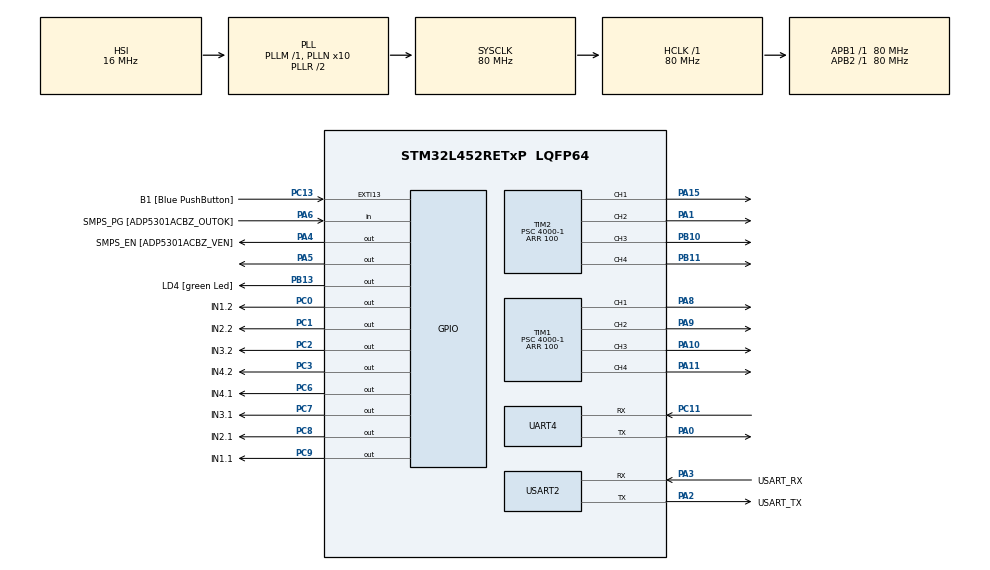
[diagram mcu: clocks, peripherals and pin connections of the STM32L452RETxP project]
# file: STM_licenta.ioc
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Mcu.Family=STM32L4
Mcu.Name=STM32L452RETxP
Mcu.Package=LQFP64
NVIC.PriorityGroup=NVIC_PRIORITYGROUP_4
NVIC.UART4_IRQn=true\:0\:0\:false\:false\:true\:true\:true\:true
PA0.Mode=Asynchronous
PA0.Signal=UART4_TX
PA1.Signal=S_TIM2_CH2
PA10.Signal=S_TIM1_CH3
PA11.Signal=S_TIM1_CH4
PA13\ (JTMS/SWDIO).GPIO_Label=TMS
PA13\ (JTMS/SWDIO).Mode=Serial_Wire
PA13\ (JTMS/SWDIO).Signal=SYS_JTMS-SWDIO
PA14\ (JTCK/SWCLK).GPIO_Label=TCK
PA14\ (JTCK/SWCLK).Mode=Serial_Wire
PA14\ (JTCK/SWCLK).Signal=SYS_JTCK-SWCLK
PA15\ (JTDI).Signal=S_TIM2_CH1
PA2.GPIO_Label=USART_TX
PA2.GPIO_Mode=GPIO_MODE_AF_PP
PA2.GPIO_PuPd=GPIO_NOPULL
PA2.GPIO_Speed=GPIO_SPEED_FREQ_VERY_HIGH
PA2.Mode=Asynchronous
PA2.Signal=USART2_TX
PA3.GPIO_Label=USART_RX
PA3.GPIO_Mode=GPIO_MODE_AF_PP
PA3.GPIO_PuPd=GPIO_NOPULL
PA3.GPIO_Speed=GPIO_SPEED_FREQ_VERY_HIGH
PA3.Mode=Asynchronous
PA3.Signal=USART2_RX
PA4.GPIO_Label=SMPS_EN [ADP5301ACBZ_VEN]
PA4.Signal=GPIO_Output
PA5.Signal=GPIO_Output
PA6.GPIO_Label=SMPS_PG [ADP5301ACBZ_OUTOK]
PA6.GPIO_PuPd=GPIO_PULLUP
PA6.Signal=GPIO_Input
PA8.Signal=S_TIM1_CH1
PA9.Signal=S_TIM1_CH2
PB10.Signal=S_TIM2_CH3
PB11.Signal=S_TIM2_CH4
PB13.GPIO_Label=LD4 [green Led]
PB13.Signal=GPIO_Output
PB3\ (JTDO/TRACESWO).GPIO_Label=SWO
PB3\ (JTDO/TRACESWO).Signal=SYS_JTDO-SWO
PC0.GPIO_Label=IN1.2
PC0.Signal=GPIO_Output
PC1.GPIO_Label=IN2.2
PC1.Signal=GPIO_Output
PC11.Mode=Asynchronous
PC11.Signal=UART4_RX
PC13.GPIO_Label=B1 [Blue PushButton]
PC13.GPIO_ModeDefaultEXTI=GPIO_MODE_IT_FALLING
PC13.GPIO_PuPd=GPIO_NOPULL
PC13.Signal=GPXTI13
PC14-OSC32_IN\ (PC14).Mode=LSE-External-Oscillator
PC14-OSC32_IN\ (PC14).Signal=RCC_OSC32_IN
PC15-OSC32_OUT\ (PC15).Mode=LSE-External-Oscillator
PC15-OSC32_OUT\ (PC15).Signal=RCC_OSC32_OUT
PC2.GPIO_Label=IN3.2
PC2.Signal=GPIO_Output
PC3.GPIO_Label=IN4.2
PC3.Signal=GPIO_Output
PC6.GPIO_Label=IN4.1
PC6.Signal=GPIO_Output
PC7.GPIO_Label=IN3.1
PC7.Signal=GPIO_Output
PC8.GPIO_Label=IN2.1
PC8.Signal=GPIO_Output
PC9.GPIO_Label=IN1.1
PC9.Signal=GPIO_Output
PH0-OSC_IN\ (PH0).GPIO_Label=MCO
PH0-OSC_IN\ (PH0).Mode=HSE-External-Clock-Source
PH0-OSC_IN\ (PH0).Signal=RCC_OSC_IN
PH1-OSC_OUT\ (PH1).Signal=RCC_OSC_OUT
ProjectManager.HeapSize=0x200
ProjectManager.StackSize=0x400
ProjectManager.TargetToolchain=STM32CubeIDE
RCC.ADCFreq_Value=64000000
RCC.AHBFreq_Value=80000000
RCC.APB1Freq_Value=80000000
RCC.APB1TimFreq_Value=80000000
RCC.APB2Freq_Value=80000000
RCC.APB2TimFreq_Value=80000000
RCC.CortexFreq_Value=80000000
RCC.HCLKFreq_Value=80000000
RCC.HSE_VALUE=8000000
RCC.HSI48_VALUE=48000000
RCC.HSI_VALUE=16000000
RCC.MSI_VALUE=4000000
RCC.PLLN=10
RCC.PLLSourceVirtual=RCC_PLLSOURCE_HSI
RCC.PREFETCH_ENABLE=1
RCC.SYSCLKFreq_VALUE=80000000
RCC.SYSCLKSource=RCC_SYSCLKSOURCE_PLLCLK
RCC.USBFreq_Value=64000000
RCC.VCOOutputFreq_Value=160000000
SH.S_TIM1_CH1.0=TIM1_CH1,PWM Generation1 CH1
SH.S_TIM1_CH2.0=TIM1_CH2,PWM Generation2 CH2
SH.S_TIM1_CH3.0=TIM1_CH3,PWM Generation3 CH3
SH.S_TIM1_CH4.0=TIM1_CH4,PWM Generation4 CH4
SH.S_TIM2_CH1.0=TIM2_CH1,PWM Generation1 CH1
SH.S_TIM2_CH2.0=TIM2_CH2,PWM Generation2 CH2
SH.S_TIM2_CH3.0=TIM2_CH3,PWM Generation3 CH3
SH.S_TIM2_CH4.0=TIM2_CH4,PWM Generation4 CH4
TIM1.Channel-PWM\ Generation1\ CH1=TIM_CHANNEL_1
TIM1.Channel-PWM\ Generation2\ CH2=TIM_CHANNEL_2
TIM1.Channel-PWM\ Generation3\ CH3=TIM_CHANNEL_3
TIM1.Channel-PWM\ Generation4\ CH4=TIM_CHANNEL_4
TIM1.Period=100
TIM1.Prescaler=4000-1
TIM2.Channel-PWM\ Generation1\ CH1=TIM_CHANNEL_1
TIM2.Channel-PWM\ Generation2\ CH2=TIM_CHANNEL_2
TIM2.Channel-PWM\ Generation3\ CH3=TIM_CHANNEL_3
TIM2.Channel-PWM\ Generation4\ CH4=TIM_CHANNEL_4
TIM2.Period=100
TIM2.Prescaler=4000-1
USART2.VirtualMode-Asynchronous=VM_ASYNC
VP_TIM1_VS_ClockSourceINT.Mode=Internal
VP_TIM2_VS_ClockSourceINT.Mode=Internal
board=NUCLEO-L452RE-P

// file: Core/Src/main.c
/* USER CODE BEGIN Header */
/**
  ******************************************************************************
  * @file           : main.c
  * @brief          : Main program body
  ******************************************************************************
  * @attention
  *
  * Copyright (c) 2025 STMicroelectronics.
  * All rights reserved.
  *
  * This software is licensed under terms that can be found in the LICENSE file
  * in the root directory of this software component.
  * If no LICENSE file comes with this software, it is provided AS-IS.
  *
  ******************************************************************************
  */
/* USER CODE END Header */
#include "main.h"

/* USER CODE BEGIN Includes */

#include <string.h>

/* USER CODE END Includes */

TIM_HandleTypeDef htim1;
TIM_HandleTypeDef htim2;

UART_HandleTypeDef huart4;
UART_HandleTypeDef huart2;

void SystemClock_Config(void);
static void MX_GPIO_Init(void);
static void MX_USART2_UART_Init(void);
static void MX_UART4_Init(void);
static void MX_TIM1_Init(void);
static void MX_TIM2_Init(void);

/* USER CODE BEGIN 0 */

uint8_t rx_byte;
char rx_buffer[32];
uint8_t rx_index = 0;

/* USER CODE END 0 */

int main(void)
{

  /* MCU Configuration--------------------------------------------------------*/

  /* Reset of all peripherals, Initializes the Flash interface and the Systick. */
  HAL_Init();

  /* Configure the system clock */
  SystemClock_Config();

  /* Initialize all configured peripherals */
  MX_GPIO_Init();
  MX_USART2_UART_Init();
  MX_UART4_Init();
  MX_TIM1_Init();
  MX_TIM2_Init();
  /* USER CODE BEGIN 2 */

  HAL_UART_Receive_IT(&huart4, &rx_byte, 1);
  HAL_TIM_PWM_Start(&htim1, TIM_CHANNEL_1);
  HAL_TIM_PWM_Start(&htim1, TIM_CHANNEL_2);
  HAL_TIM_PWM_Start(&htim1, TIM_CHANNEL_3);
  HAL_TIM_PWM_Start(&htim1, TIM_CHANNEL_4);
  HAL_TIM_PWM_Start(&htim2, TIM_CHANNEL_1);
  HAL_TIM_PWM_Start(&htim2, TIM_CHANNEL_2);
  HAL_TIM_PWM_Start(&htim2, TIM_CHANNEL_3);
  HAL_TIM_PWM_Start(&htim2, TIM_CHANNEL_4);

  /* USER CODE END 2 */

  /* Infinite loop */
  while (1)
  {

  }
}

void SystemClock_Config(void)
{
  RCC_OscInitTypeDef RCC_OscInitStruct = {0};
  RCC_ClkInitTypeDef RCC_ClkInitStruct = {0};

  /** Configure the main internal regulator output voltage
  */
  if (HAL_PWREx_ControlVoltageScaling(PWR_REGULATOR_VOLTAGE_SCALE1) != HAL_OK)
  {
    Error_Handler();
  }

  /** Initializes the RCC Oscillators according to the specified parameters
  * in the RCC_OscInitTypeDef structure.
  */
  RCC_OscInitStruct.OscillatorType = RCC_OSCILLATORTYPE_HSI;
  RCC_OscInitStruct.HSIState = RCC_HSI_ON;
  RCC_OscInitStruct.HSICalibrationValue = 64;
  RCC_OscInitStruct.PLL.PLLState = RCC_PLL_ON;
  RCC_OscInitStruct.PLL.PLLSource = RCC_PLLSOURCE_HSI;
  RCC_OscInitStruct.PLL.PLLM = 1;
  RCC_OscInitStruct.PLL.PLLN = 10;
  RCC_OscInitStruct.PLL.PLLP = RCC_PLLP_DIV7;
  RCC_OscInitStruct.PLL.PLLQ = RCC_PLLQ_DIV2;
  RCC_OscInitStruct.PLL.PLLR = RCC_PLLR_DIV2;
  if (HAL_RCC_OscConfig(&RCC_OscInitStruct) != HAL_OK)
  {
    Error_Handler();
  }

  /** Initializes the CPU, AHB and APB buses clocks
  */
  RCC_ClkInitStruct.ClockType = RCC_CLOCKTYPE_HCLK|RCC_CLOCKTYPE_SYSCLK
                              |RCC_CLOCKTYPE_PCLK1|RCC_CLOCKTYPE_PCLK2;
  RCC_ClkInitStruct.SYSCLKSource = RCC_SYSCLKSOURCE_PLLCLK;
  RCC_ClkInitStruct.AHBCLKDivider = RCC_SYSCLK_DIV1;
  RCC_ClkInitStruct.APB1CLKDivider = RCC_HCLK_DIV1;
  RCC_ClkInitStruct.APB2CLKDivider = RCC_HCLK_DIV1;

  if (HAL_RCC_ClockConfig(&RCC_ClkInitStruct, FLASH_LATENCY_4) != HAL_OK)
  {
    Error_Handler();
  }
}

static void MX_TIM1_Init(void)
{

  TIM_ClockConfigTypeDef sClockSourceConfig = {0};
  TIM_MasterConfigTypeDef sMasterConfig = {0};
  TIM_OC_InitTypeDef sConfigOC = {0};
  TIM_BreakDeadTimeConfigTypeDef sBreakDeadTimeConfig = {0};

  htim1.Instance = TIM1;
  htim1.Init.Prescaler = 4000-1;
  htim1.Init.CounterMode = TIM_COUNTERMODE_UP;
  htim1.Init.Period = 100;
  htim1.Init.ClockDivision = TIM_CLOCKDIVISION_DIV1;
  htim1.Init.RepetitionCounter = 0;
  htim1.Init.AutoReloadPreload = TIM_AUTORELOAD_PRELOAD_DISABLE;
  if (HAL_TIM_Base_Init(&htim1) != HAL_OK)
  {
    Error_Handler();
  }
  sClockSourceConfig.ClockSource = TIM_CLOCKSOURCE_INTERNAL;
  if (HAL_TIM_ConfigClockSource(&htim1, &sClockSourceConfig) != HAL_OK)
  {
    Error_Handler();
  }
  if (HAL_TIM_PWM_Init(&htim1) != HAL_OK)
  {
    Error_Handler();
  }
  sMasterConfig.MasterOutputTrigger = TIM_TRGO_RESET;
  sMasterConfig.MasterOutputTrigger2 = TIM_TRGO2_RESET;
  sMasterConfig.MasterSlaveMode = TIM_MASTERSLAVEMODE_DISABLE;
  if (HAL_TIMEx_MasterConfigSynchronization(&htim1, &sMasterConfig) != HAL_OK)
  {
    Error_Handler();
  }
  sConfigOC.OCMode = TIM_OCMODE_PWM1;
  sConfigOC.Pulse = 0;
  sConfigOC.OCPolarity = TIM_OCPOLARITY_HIGH;
  sConfigOC.OCNPolarity = TIM_OCNPOLARITY_HIGH;
  sConfigOC.OCFastMode = TIM_OCFAST_DISABLE;
  sConfigOC.OCIdleState = TIM_OCIDLESTATE_RESET;
  sConfigOC.OCNIdleState = TIM_OCNIDLESTATE_RESET;
  if (HAL_TIM_PWM_ConfigChannel(&htim1, &sConfigOC, TIM_CHANNEL_1) != HAL_OK)
  {
    Error_Handler();
  }
  if (HAL_TIM_PWM_ConfigChannel(&htim1, &sConfigOC, TIM_CHANNEL_2) != HAL_OK)
  {
    Error_Handler();
  }
  if (HAL_TIM_PWM_ConfigChannel(&htim1, &sConfigOC, TIM_CHANNEL_3) != HAL_OK)
  {
    Error_Handler();
  }
  if (HAL_TIM_PWM_ConfigChannel(&htim1, &sConfigOC, TIM_CHANNEL_4) != HAL_OK)
  {
    Error_Handler();
  }
  sBreakDeadTimeConfig.OffStateRunMode = TIM_OSSR_DISABLE;
  sBreakDeadTimeConfig.OffStateIDLEMode = TIM_OSSI_DISABLE;
  sBreakDeadTimeConfig.LockLevel = TIM_LOCKLEVEL_OFF;
  sBreakDeadTimeConfig.DeadTime = 0;
  sBreakDeadTimeConfig.BreakState = TIM_BREAK_DISABLE;
  sBreakDeadTimeConfig.BreakPolarity = TIM_BREAKPOLARITY_HIGH;
  sBreakDeadTimeConfig.BreakFilter = 0;
  sBreakDeadTimeConfig.Break2State = TIM_BREAK2_DISABLE;
  sBreakDeadTimeConfig.Break2Polarity = TIM_BREAK2POLARITY_HIGH;
  sBreakDeadTimeConfig.Break2Filter = 0;
  sBreakDeadTimeConfig.AutomaticOutput = TIM_AUTOMATICOUTPUT_DISABLE;
  if (HAL_TIMEx_ConfigBreakDeadTime(&htim1, &sBreakDeadTimeConfig) != HAL_OK)
  {
    Error_Handler();
  }
  HAL_TIM_MspPostInit(&htim1);

}

static void MX_TIM2_Init(void)
{

  TIM_ClockConfigTypeDef sClockSourceConfig = {0};
  TIM_MasterConfigTypeDef sMasterConfig = {0};
  TIM_OC_InitTypeDef sConfigOC = {0};

  htim2.Instance = TIM2;
  htim2.Init.Prescaler = 4000-1;
  htim2.Init.CounterMode = TIM_COUNTERMODE_UP;
  htim2.Init.Period = 100;
  htim2.Init.ClockDivision = TIM_CLOCKDIVISION_DIV1;
  htim2.Init.AutoReloadPreload = TIM_AUTORELOAD_PRELOAD_DISABLE;
  if (HAL_TIM_Base_Init(&htim2) != HAL_OK)
  {
    Error_Handler();
  }
  sClockSourceConfig.ClockSource = TIM_CLOCKSOURCE_INTERNAL;
  if (HAL_TIM_ConfigClockSource(&htim2, &sClockSourceConfig) != HAL_OK)
  {
    Error_Handler();
  }
  if (HAL_TIM_PWM_Init(&htim2) != HAL_OK)
  {
    Error_Handler();
  }
  sMasterConfig.MasterOutputTrigger = TIM_TRGO_RESET;
  sMasterConfig.MasterSlaveMode = TIM_MASTERSLAVEMODE_DISABLE;
  if (HAL_TIMEx_MasterConfigSynchronization(&htim2, &sMasterConfig) != HAL_OK)
  {
    Error_Handler();
  }
  sConfigOC.OCMode = TIM_OCMODE_PWM1;
  sConfigOC.Pulse = 0;
  sConfigOC.OCPolarity = TIM_OCPOLARITY_HIGH;
  sConfigOC.OCFastMode = TIM_OCFAST_DISABLE;
  if (HAL_TIM_PWM_ConfigChannel(&htim2, &sConfigOC, TIM_CHANNEL_1) != HAL_OK)
  {
    Error_Handler();
  }
  if (HAL_TIM_PWM_ConfigChannel(&htim2, &sConfigOC, TIM_CHANNEL_2) != HAL_OK)
  {
    Error_Handler();
  }
  if (HAL_TIM_PWM_ConfigChannel(&htim2, &sConfigOC, TIM_CHANNEL_3) != HAL_OK)
  {
    Error_Handler();
  }
  if (HAL_TIM_PWM_ConfigChannel(&htim2, &sConfigOC, TIM_CHANNEL_4) != HAL_OK)
  {
    Error_Handler();
  }
  HAL_TIM_MspPostInit(&htim2);

}

static void MX_UART4_Init(void)
{

  huart4.Instance = UART4;
  huart4.Init.BaudRate = 115200;
  huart4.Init.WordLength = UART_WORDLENGTH_8B;
  huart4.Init.StopBits = UART_STOPBITS_1;
  huart4.Init.Parity = UART_PARITY_NONE;
  huart4.Init.Mode = UART_MODE_TX_RX;
  huart4.Init.HwFlowCtl = UART_HWCONTROL_NONE;
  huart4.Init.OverSampling = UART_OVERSAMPLING_16;
  huart4.Init.OneBitSampling = UART_ONE_BIT_SAMPLE_DISABLE;
  huart4.AdvancedInit.AdvFeatureInit = UART_ADVFEATURE_NO_INIT;
  if (HAL_UART_Init(&huart4) != HAL_OK)
  {
    Error_Handler();
  }

}

static void MX_USART2_UART_Init(void)
{

  huart2.Instance = USART2;
  huart2.Init.BaudRate = 115200;
  huart2.Init.WordLength = UART_WORDLENGTH_8B;
  huart2.Init.StopBits = UART_STOPBITS_1;
  huart2.Init.Parity = UART_PARITY_NONE;
  huart2.Init.Mode = UART_MODE_TX_RX;
  huart2.Init.HwFlowCtl = UART_HWCONTROL_NONE;
  huart2.Init.OverSampling = UART_OVERSAMPLING_16;
  huart2.Init.OneBitSampling = UART_ONE_BIT_SAMPLE_DISABLE;
  huart2.AdvancedInit.AdvFeatureInit = UART_ADVFEATURE_NO_INIT;
  if (HAL_UART_Init(&huart2) != HAL_OK)
  {
    Error_Handler();
  }

}

static void MX_GPIO_Init(void)
{
  GPIO_InitTypeDef GPIO_InitStruct = {0};

  /* GPIO Ports Clock Enable */
  __HAL_RCC_GPIOC_CLK_ENABLE();
  __HAL_RCC_GPIOH_CLK_ENABLE();
  __HAL_RCC_GPIOA_CLK_ENABLE();
  __HAL_RCC_GPIOB_CLK_ENABLE();

  /*Configure GPIO pin Output Level */
  HAL_GPIO_WritePin(GPIOC, IN1_2_Pin|IN2_2_Pin|IN3_2_Pin|IN4_2_Pin
                          |IN4_1_Pin|IN3_1_Pin|IN2_1_Pin|IN1_1_Pin, GPIO_PIN_RESET);

  /*Configure GPIO pin Output Level */
  HAL_GPIO_WritePin(GPIOA, SMPS_EN_Pin|GPIO_PIN_5, GPIO_PIN_RESET);

  /*Configure GPIO pin Output Level */
  HAL_GPIO_WritePin(LD4_GPIO_Port, LD4_Pin, GPIO_PIN_RESET);

  /*Configure GPIO pin : B1_Pin */
  GPIO_InitStruct.Pin = B1_Pin;
  GPIO_InitStruct.Mode = GPIO_MODE_IT_FALLING;
  GPIO_InitStruct.Pull = GPIO_NOPULL;
  HAL_GPIO_Init(B1_GPIO_Port, &GPIO_InitStruct);

  /*Configure GPIO pins : IN1_2_Pin IN2_2_Pin IN3_2_Pin IN4_2_Pin
                           IN4_1_Pin IN3_1_Pin IN2_1_Pin IN1_1_Pin */
  GPIO_InitStruct.Pin = IN1_2_Pin|IN2_2_Pin|IN3_2_Pin|IN4_2_Pin
                          |IN4_1_Pin|IN3_1_Pin|IN2_1_Pin|IN1_1_Pin;
  GPIO_InitStruct.Mode = GPIO_MODE_OUTPUT_PP;
  GPIO_InitStruct.Pull = GPIO_NOPULL;
  GPIO_InitStruct.Speed = GPIO_SPEED_FREQ_LOW;
  HAL_GPIO_Init(GPIOC, &GPIO_InitStruct);

  /*Configure GPIO pins : SMPS_EN_Pin PA5 */
  GPIO_InitStruct.Pin = SMPS_EN_Pin|GPIO_PIN_5;
  GPIO_InitStruct.Mode = GPIO_MODE_OUTPUT_PP;
  GPIO_InitStruct.Pull = GPIO_NOPULL;
  GPIO_InitStruct.Speed = GPIO_SPEED_FREQ_LOW;
  HAL_GPIO_Init(GPIOA, &GPIO_InitStruct);

  /*Configure GPIO pin : SMPS_PG_Pin */
  GPIO_InitStruct.Pin = SMPS_PG_Pin;
  GPIO_InitStruct.Mode = GPIO_MODE_INPUT;
  GPIO_InitStruct.Pull = GPIO_PULLUP;
  HAL_GPIO_Init(SMPS_PG_GPIO_Port, &GPIO_InitStruct);

  /*Configure GPIO pin : LD4_Pin */
  GPIO_InitStruct.Pin = LD4_Pin;
  GPIO_InitStruct.Mode = GPIO_MODE_OUTPUT_PP;
  GPIO_InitStruct.Pull = GPIO_NOPULL;
  GPIO_InitStruct.Speed = GPIO_SPEED_FREQ_LOW;
  HAL_GPIO_Init(LD4_GPIO_Port, &GPIO_InitStruct);

}

/* USER CODE BEGIN 4 */

void HAL_UART_RxCpltCallback(UART_HandleTypeDef *huart){
  if (huart->Instance == UART4){
	  HAL_UART_Receive_IT(&huart4, &rx_byte, sizeof(rx_byte));
	  if (rx_byte == 0x01){
    	  HAL_GPIO_WritePin(IN1_1_GPIO_Port, IN1_1_Pin, GPIO_PIN_SET);
    	  HAL_GPIO_WritePin(IN2_1_GPIO_Port, IN2_1_Pin, GPIO_PIN_RESET);
    	  HAL_GPIO_WritePin(IN3_1_GPIO_Port, IN3_1_Pin, GPIO_PIN_SET);
    	  HAL_GPIO_WritePin(IN4_1_GPIO_Port, IN4_1_Pin, GPIO_PIN_RESET);
    	  HAL_GPIO_WritePin(IN1_2_GPIO_Port, IN1_2_Pin, GPIO_PIN_RESET);
    	  HAL_GPIO_WritePin(IN2_2_GPIO_Port, IN2_2_Pin, GPIO_PIN_RESET);
    	  HAL_GPIO_WritePin(IN3_2_GPIO_Port, IN3_2_Pin, GPIO_PIN_RESET);
    	  HAL_GPIO_WritePin(IN4_2_GPIO_Port, IN4_2_Pin, GPIO_PIN_RESET);
    	  HAL_GPIO_WritePin(GPIOB, GPIO_PIN_13, GPIO_PIN_SET);
    	  __HAL_TIM_SET_COMPARE(&htim1, TIM_CHANNEL_1, 20);
    	  __HAL_TIM_SET_COMPARE(&htim1, TIM_CHANNEL_2, 20);
      }
	  else if (rx_byte == 0x02){
    	  HAL_GPIO_WritePin(IN1_1_GPIO_Port, IN1_1_Pin, GPIO_PIN_SET);
    	  HAL_GPIO_WritePin(IN2_1_GPIO_Port, IN2_1_Pin, GPIO_PIN_RESET);
    	  HAL_GPIO_WritePin(IN3_1_GPIO_Port, IN3_1_Pin, GPIO_PIN_SET);
    	  HAL_GPIO_WritePin(IN4_1_GPIO_Port, IN4_1_Pin, GPIO_PIN_RESET);
    	  HAL_GPIO_WritePin(IN1_2_GPIO_Port, IN1_2_Pin, GPIO_PIN_RESET);
    	  HAL_GPIO_WritePin(IN2_2_GPIO_Port, IN2_2_Pin, GPIO_PIN_RESET);
    	  HAL_GPIO_WritePin(IN3_2_GPIO_Port, IN3_2_Pin, GPIO_PIN_RESET);
    	  HAL_GPIO_WritePin(IN4_2_GPIO_Port, IN4_2_Pin, GPIO_PIN_RESET);
    	  HAL_GPIO_WritePin(GPIOB, GPIO_PIN_13, GPIO_PIN_SET);
    	  __HAL_TIM_SET_COMPARE(&htim1, TIM_CHANNEL_1, 40);
    	  __HAL_TIM_SET_COMPARE(&htim1, TIM_CHANNEL_2, 40);
	    	}
	  else if (rx_byte == 0x03){
    	  HAL_GPIO_WritePin(IN1_1_GPIO_Port, IN1_1_Pin, GPIO_PIN_SET);
    	  HAL_GPIO_WritePin(IN2_1_GPIO_Port, IN2_1_Pin, GPIO_PIN_RESET);
    	  HAL_GPIO_WritePin(IN3_1_GPIO_Port, IN3_1_Pin, GPIO_PIN_SET);
    	  HAL_GPIO_WritePin(IN4_1_GPIO_Port, IN4_1_Pin, GPIO_PIN_RESET);
    	  HAL_GPIO_WritePin(IN1_2_GPIO_Port, IN1_2_Pin, GPIO_PIN_RESET);
    	  HAL_GPIO_WritePin(IN2_2_GPIO_Port, IN2_2_Pin, GPIO_PIN_RESET);
    	  HAL_GPIO_WritePin(IN3_2_GPIO_Port, IN3_2_Pin, GPIO_PIN_RESET);
    	  HAL_GPIO_WritePin(IN4_2_GPIO_Port, IN4_2_Pin, GPIO_PIN_RESET);
    	  HAL_GPIO_WritePin(GPIOB, GPIO_PIN_13, GPIO_PIN_SET);
    	  __HAL_TIM_SET_COMPARE(&htim1, TIM_CHANNEL_1, 60);
    	  __HAL_TIM_SET_COMPARE(&htim1, TIM_CHANNEL_2, 60);
	  	    	}
	  else if (rx_byte == 0x04){
    	  HAL_GPIO_WritePin(IN1_1_GPIO_Port, IN1_1_Pin, GPIO_PIN_SET);
    	  HAL_GPIO_WritePin(IN2_1_GPIO_Port, IN2_1_Pin, GPIO_PIN_RESET);
    	  HAL_GPIO_WritePin(IN3_1_GPIO_Port, IN3_1_Pin, GPIO_PIN_SET);
    	  HAL_GPIO_WritePin(IN4_1_GPIO_Port, IN4_1_Pin, GPIO_PIN_RESET);
    	  HAL_GPIO_WritePin(IN1_2_GPIO_Port, IN1_2_Pin, GPIO_PIN_RESET);
    	  HAL_GPIO_WritePin(IN2_2_GPIO_Port, IN2_2_Pin, GPIO_PIN_RESET);
    	  HAL_GPIO_WritePin(IN3_2_GPIO_Port, IN3_2_Pin, GPIO_PIN_RESET);
    	  HAL_GPIO_WritePin(IN4_2_GPIO_Port, IN4_2_Pin, GPIO_PIN_RESET);
    	  HAL_GPIO_WritePin(GPIOB, GPIO_PIN_13, GPIO_PIN_SET);
    	  __HAL_TIM_SET_COMPARE(&htim1, TIM_CHANNEL_1, 80);
    	  __HAL_TIM_SET_COMPARE(&htim1, TIM_CHANNEL_2, 80);
	  	  	    }
	  else if (rx_byte == 0x05){
    	  HAL_GPIO_WritePin(IN1_1_GPIO_Port, IN1_1_Pin, GPIO_PIN_SET);
    	  HAL_GPIO_WritePin(IN2_1_GPIO_Port, IN2_1_Pin, GPIO_PIN_RESET);
    	  HAL_GPIO_WritePin(IN3_1_GPIO_Port, IN3_1_Pin, GPIO_PIN_SET);
    	  HAL_GPIO_WritePin(IN4_1_GPIO_Port, IN4_1_Pin, GPIO_PIN_RESET);
    	  HAL_GPIO_WritePin(IN1_2_GPIO_Port, IN1_2_Pin, GPIO_PIN_RESET);
    	  HAL_GPIO_WritePin(IN2_2_GPIO_Port, IN2_2_Pin, GPIO_PIN_RESET);
    	  HAL_GPIO_WritePin(IN3_2_GPIO_Port, IN3_2_Pin, GPIO_PIN_RESET);
    	  HAL_GPIO_WritePin(IN4_2_GPIO_Port, IN4_2_Pin, GPIO_PIN_RESET);
    	  HAL_GPIO_WritePin(GPIOB, GPIO_PIN_13, GPIO_PIN_SET);
    	  __HAL_TIM_SET_COMPARE(&htim1, TIM_CHANNEL_1, 100);
    	  __HAL_TIM_SET_COMPARE(&htim1, TIM_CHANNEL_2, 100);
	  	    	}
	  else if (rx_byte == 0x06){
    	  HAL_GPIO_WritePin(IN1_1_GPIO_Port, IN1_1_Pin, GPIO_PIN_RESET);
    	  HAL_GPIO_WritePin(IN2_1_GPIO_Port, IN2_1_Pin, GPIO_PIN_SET);
    	  HAL_GPIO_WritePin(IN3_1_GPIO_Port, IN3_1_Pin, GPIO_PIN_RESET);
    	  HAL_GPIO_WritePin(IN4_1_GPIO_Port, IN4_1_Pin, GPIO_PIN_SET);
    	  HAL_GPIO_WritePin(IN1_2_GPIO_Port, IN1_2_Pin, GPIO_PIN_RESET);
    	  HAL_GPIO_WritePin(IN2_2_GPIO_Port, IN2_2_Pin, GPIO_PIN_RESET);
    	  HAL_GPIO_WritePin(IN3_2_GPIO_Port, IN3_2_Pin, GPIO_PIN_RESET);
    	  HAL_GPIO_WritePin(IN4_2_GPIO_Port, IN4_2_Pin, GPIO_PIN_RESET);
    	  HAL_GPIO_WritePin(GPIOB, GPIO_PIN_13, GPIO_PIN_SET);
    	  __HAL_TIM_SET_COMPARE(&htim1, TIM_CHANNEL_1, 20);
    	  __HAL_TIM_SET_COMPARE(&htim1, TIM_CHANNEL_2, 20);
	  	    	}
	  else if (rx_byte == 0x07){
    	  HAL_GPIO_WritePin(IN1_1_GPIO_Port, IN1_1_Pin, GPIO_PIN_RESET);
    	  HAL_GPIO_WritePin(IN2_1_GPIO_Port, IN2_1_Pin, GPIO_PIN_SET);
    	  HAL_GPIO_WritePin(IN3_1_GPIO_Port, IN3_1_Pin, GPIO_PIN_RESET);
    	  HAL_GPIO_WritePin(IN4_1_GPIO_Port, IN4_1_Pin, GPIO_PIN_SET);
    	  HAL_GPIO_WritePin(IN1_2_GPIO_Port, IN1_2_Pin, GPIO_PIN_RESET);
    	  HAL_GPIO_WritePin(IN2_2_GPIO_Port, IN2_2_Pin, GPIO_PIN_RESET);
    	  HAL_GPIO_WritePin(IN3_2_GPIO_Port, IN3_2_Pin, GPIO_PIN_RESET);
    	  HAL_GPIO_WritePin(IN4_2_GPIO_Port, IN4_2_Pin, GPIO_PIN_RESET);
    	  HAL_GPIO_WritePin(GPIOB, GPIO_PIN_13, GPIO_PIN_SET);
    	  __HAL_TIM_SET_COMPARE(&htim1, TIM_CHANNEL_1, 40);
    	  __HAL_TIM_SET_COMPARE(&htim1, TIM_CHANNEL_2, 40);
	  	    	}
	  else if (rx_byte == 0x08){
    	  HAL_GPIO_WritePin(IN1_1_GPIO_Port, IN1_1_Pin, GPIO_PIN_RESET);
    	  HAL_GPIO_WritePin(IN2_1_GPIO_Port, IN2_1_Pin, GPIO_PIN_SET);
    	  HAL_GPIO_WritePin(IN3_1_GPIO_Port, IN3_1_Pin, GPIO_PIN_RESET);
    	  HAL_GPIO_WritePin(IN4_1_GPIO_Port, IN4_1_Pin, GPIO_PIN_SET);
    	  HAL_GPIO_WritePin(IN1_2_GPIO_Port, IN1_2_Pin, GPIO_PIN_RESET);
    	  HAL_GPIO_WritePin(IN2_2_GPIO_Port, IN2_2_Pin, GPIO_PIN_RESET);
    	  HAL_GPIO_WritePin(IN3_2_GPIO_Port, IN3_2_Pin, GPIO_PIN_RESET);
    	  HAL_GPIO_WritePin(IN4_2_GPIO_Port, IN4_2_Pin, GPIO_PIN_RESET);
    	  HAL_GPIO_WritePin(GPIOB, GPIO_PIN_13, GPIO_PIN_SET);
    	  __HAL_TIM_SET_COMPARE(&htim1, TIM_CHANNEL_1, 60);
    	  __HAL_TIM_SET_COMPARE(&htim1, TIM_CHANNEL_2, 60);
	  	    	}
	  else if (rx_byte == 0x09){
    	  HAL_GPIO_WritePin(IN1_1_GPIO_Port, IN1_1_Pin, GPIO_PIN_RESET);
    	  HAL_GPIO_WritePin(IN2_1_GPIO_Port, IN2_1_Pin, GPIO_PIN_SET);
    	  HAL_GPIO_WritePin(IN3_1_GPIO_Port, IN3_1_Pin, GPIO_PIN_RESET);
    	  HAL_GPIO_WritePin(IN4_1_GPIO_Port, IN4_1_Pin, GPIO_PIN_SET);
    	  HAL_GPIO_WritePin(IN1_2_GPIO_Port, IN1_2_Pin, GPIO_PIN_RESET);
    	  HAL_GPIO_WritePin(IN2_2_GPIO_Port, IN2_2_Pin, GPIO_PIN_RESET);
    	  HAL_GPIO_WritePin(IN3_2_GPIO_Port, IN3_2_Pin, GPIO_PIN_RESET);
    	  HAL_GPIO_WritePin(IN4_2_GPIO_Port, IN4_2_Pin, GPIO_PIN_RESET);
    	  HAL_GPIO_WritePin(GPIOB, GPIO_PIN_13, GPIO_PIN_SET);
    	  __HAL_TIM_SET_COMPARE(&htim1, TIM_CHANNEL_1, 80);
    	  __HAL_TIM_SET_COMPARE(&htim1, TIM_CHANNEL_2, 80);
	  	    	}
	  else if (rx_byte == 0x0A){
    	  HAL_GPIO_WritePin(IN1_1_GPIO_Port, IN1_1_Pin, GPIO_PIN_RESET);
    	  HAL_GPIO_WritePin(IN2_1_GPIO_Port, IN2_1_Pin, GPIO_PIN_SET);
    	  HAL_GPIO_WritePin(IN3_1_GPIO_Port, IN3_1_Pin, GPIO_PIN_RESET);
    	  HAL_GPIO_WritePin(IN4_1_GPIO_Port, IN4_1_Pin, GPIO_PIN_SET);
    	  HAL_GPIO_WritePin(IN1_2_GPIO_Port, IN1_2_Pin, GPIO_PIN_RESET);
    	  HAL_GPIO_WritePin(IN2_2_GPIO_Port, IN2_2_Pin, GPIO_PIN_RESET);
    	  HAL_GPIO_WritePin(IN3_2_GPIO_Port, IN3_2_Pin, GPIO_PIN_RESET);
    	  HAL_GPIO_WritePin(IN4_2_GPIO_Port, IN4_2_Pin, GPIO_PIN_RESET);
    	  HAL_GPIO_WritePin(GPIOB, GPIO_PIN_13, GPIO_PIN_SET);
    	  __HAL_TIM_SET_COMPARE(&htim1, TIM_CHANNEL_1, 100);
    	  __HAL_TIM_SET_COMPARE(&htim1, TIM_CHANNEL_2, 100);
	  	    	}
	  else if (rx_byte == 0x0B){
    	  HAL_GPIO_WritePin(IN1_1_GPIO_Port, IN1_1_Pin, GPIO_PIN_RESET);
    	  HAL_GPIO_WritePin(IN2_1_GPIO_Port, IN2_1_Pin, GPIO_PIN_RESET);
    	  HAL_GPIO_WritePin(IN3_1_GPIO_Port, IN3_1_Pin, GPIO_PIN_RESET);
    	  HAL_GPIO_WritePin(IN4_1_GPIO_Port, IN4_1_Pin, GPIO_PIN_RESET);
    	  HAL_GPIO_WritePin(IN1_2_GPIO_Port, IN1_2_Pin, GPIO_PIN_SET);
    	  HAL_GPIO_WritePin(IN2_2_GPIO_Port, IN2_2_Pin, GPIO_PIN_RESET);
    	  HAL_GPIO_WritePin(IN3_2_GPIO_Port, IN3_2_Pin, GPIO_PIN_SET);
    	  HAL_GPIO_WritePin(IN4_2_GPIO_Port, IN4_2_Pin, GPIO_PIN_RESET);
    	  HAL_GPIO_WritePin(GPIOB, GPIO_PIN_13, GPIO_PIN_SET);
    	  __HAL_TIM_SET_COMPARE(&htim1, TIM_CHANNEL_3, 20);
    	  __HAL_TIM_SET_COMPARE(&htim1, TIM_CHANNEL_4, 20);
	  	    	}
	  else if (rx_byte == 0x0C){
    	  HAL_GPIO_WritePin(IN1_1_GPIO_Port, IN1_1_Pin, GPIO_PIN_RESET);
    	  HAL_GPIO_WritePin(IN2_1_GPIO_Port, IN2_1_Pin, GPIO_PIN_RESET);
    	  HAL_GPIO_WritePin(IN3_1_GPIO_Port, IN3_1_Pin, GPIO_PIN_RESET);
    	  HAL_GPIO_WritePin(IN4_1_GPIO_Port, IN4_1_Pin, GPIO_PIN_RESET);
    	  HAL_GPIO_WritePin(IN1_2_GPIO_Port, IN1_2_Pin, GPIO_PIN_SET);
    	  HAL_GPIO_WritePin(IN2_2_GPIO_Port, IN2_2_Pin, GPIO_PIN_RESET);
    	  HAL_GPIO_WritePin(IN3_2_GPIO_Port, IN3_2_Pin, GPIO_PIN_SET);
    	  HAL_GPIO_WritePin(IN4_2_GPIO_Port, IN4_2_Pin, GPIO_PIN_RESET);
    	  HAL_GPIO_WritePin(GPIOB, GPIO_PIN_13, GPIO_PIN_SET);
    	  __HAL_TIM_SET_COMPARE(&htim1, TIM_CHANNEL_3, 40);
    	  __HAL_TIM_SET_COMPARE(&htim1, TIM_CHANNEL_4, 40);
	  	    	}
	  else if (rx_byte == 0x0D){
    	  HAL_GPIO_WritePin(IN1_1_GPIO_Port, IN1_1_Pin, GPIO_PIN_RESET);
    	  HAL_GPIO_WritePin(IN2_1_GPIO_Port, IN2_1_Pin, GPIO_PIN_RESET);
    	  HAL_GPIO_WritePin(IN3_1_GPIO_Port, IN3_1_Pin, GPIO_PIN_RESET);
    	  HAL_GPIO_WritePin(IN4_1_GPIO_Port, IN4_1_Pin, GPIO_PIN_RESET);
    	  HAL_GPIO_WritePin(IN1_2_GPIO_Port, IN1_2_Pin, GPIO_PIN_SET);
    	  HAL_GPIO_WritePin(IN2_2_GPIO_Port, IN2_2_Pin, GPIO_PIN_RESET);
    	  HAL_GPIO_WritePin(IN3_2_GPIO_Port, IN3_2_Pin, GPIO_PIN_SET);
    	  HAL_GPIO_WritePin(IN4_2_GPIO_Port, IN4_2_Pin, GPIO_PIN_RESET);
    	  HAL_GPIO_WritePin(GPIOB, GPIO_PIN_13, GPIO_PIN_SET);
    	  __HAL_TIM_SET_COMPARE(&htim1, TIM_CHANNEL_3, 60);
    	  __HAL_TIM_SET_COMPARE(&htim1, TIM_CHANNEL_4, 60);
	  	    	}
	  else if (rx_byte == 0x0E){
    	  HAL_GPIO_WritePin(IN1_1_GPIO_Port, IN1_1_Pin, GPIO_PIN_RESET);
    	  HAL_GPIO_WritePin(IN2_1_GPIO_Port, IN2_1_Pin, GPIO_PIN_RESET);
    	  HAL_GPIO_WritePin(IN3_1_GPIO_Port, IN3_1_Pin, GPIO_PIN_RESET);
    	  HAL_GPIO_WritePin(IN4_1_GPIO_Port, IN4_1_Pin, GPIO_PIN_RESET);
    	  HAL_GPIO_WritePin(IN1_2_GPIO_Port, IN1_2_Pin, GPIO_PIN_SET);
    	  HAL_GPIO_WritePin(IN2_2_GPIO_Port, IN2_2_Pin, GPIO_PIN_RESET);
    	  HAL_GPIO_WritePin(IN3_2_GPIO_Port, IN3_2_Pin, GPIO_PIN_SET);
    	  HAL_GPIO_WritePin(IN4_2_GPIO_Port, IN4_2_Pin, GPIO_PIN_RESET);
    	  HAL_GPIO_WritePin(GPIOB, GPIO_PIN_13, GPIO_PIN_SET);
    	  __HAL_TIM_SET_COMPARE(&htim1, TIM_CHANNEL_3, 80);
    	  __HAL_TIM_SET_COMPARE(&htim1, TIM_CHANNEL_4, 80);
	  	    	}
	  else if (rx_byte == 0x0F){
    	  HAL_GPIO_WritePin(IN1_1_GPIO_Port, IN1_1_Pin, GPIO_PIN_RESET);
    	  HAL_GPIO_WritePin(IN2_1_GPIO_Port, IN2_1_Pin, GPIO_PIN_RESET);
    	  HAL_GPIO_WritePin(IN3_1_GPIO_Port, IN3_1_Pin, GPIO_PIN_RESET);
    	  HAL_GPIO_WritePin(IN4_1_GPIO_Port, IN4_1_Pin, GPIO_PIN_RESET);
    	  HAL_GPIO_WritePin(IN1_2_GPIO_Port, IN1_2_Pin, GPIO_PIN_SET);
    	  HAL_GPIO_WritePin(IN2_2_GPIO_Port, IN2_2_Pin, GPIO_PIN_RESET);
    	  HAL_GPIO_WritePin(IN3_2_GPIO_Port, IN3_2_Pin, GPIO_PIN_SET);
    	  HAL_GPIO_WritePin(IN4_2_GPIO_Port, IN4_2_Pin, GPIO_PIN_RESET);
    	  HAL_GPIO_WritePin(GPIOB, GPIO_PIN_13, GPIO_PIN_SET);
    	  __HAL_TIM_SET_COMPARE(&htim1, TIM_CHANNEL_3, 100);
    	  __HAL_TIM_SET_COMPARE(&htim1, TIM_CHANNEL_4, 100);
	  	    	}
	  else if (rx_byte == 0x10){
    	  HAL_GPIO_WritePin(IN1_1_GPIO_Port, IN1_1_Pin, GPIO_PIN_RESET);
    	  HAL_GPIO_WritePin(IN2_1_GPIO_Port, IN2_1_Pin, GPIO_PIN_RESET);
    	  HAL_GPIO_WritePin(IN3_1_GPIO_Port, IN3_1_Pin, GPIO_PIN_RESET);
    	  HAL_GPIO_WritePin(IN4_1_GPIO_Port, IN4_1_Pin, GPIO_PIN_RESET);
    	  HAL_GPIO_WritePin(IN1_2_GPIO_Port, IN1_2_Pin, GPIO_PIN_RESET);
    	  HAL_GPIO_WritePin(IN2_2_GPIO_Port, IN2_2_Pin, GPIO_PIN_SET);
    	  HAL_GPIO_WritePin(IN3_2_GPIO_Port, IN3_2_Pin, GPIO_PIN_RESET);
    	  HAL_GPIO_WritePin(IN4_2_GPIO_Port, IN4_2_Pin, GPIO_PIN_SET);
    	  HAL_GPIO_WritePin(GPIOB, GPIO_PIN_13, GPIO_PIN_SET);
    	  __HAL_TIM_SET_COMPARE(&htim1, TIM_CHANNEL_3, 20);
    	  __HAL_TIM_SET_COMPARE(&htim1, TIM_CHANNEL_4, 20);
	  	    	}
	  else if (rx_byte == 0x11){
    	  HAL_GPIO_WritePin(IN1_1_GPIO_Port, IN1_1_Pin, GPIO_PIN_RESET);
    	  HAL_GPIO_WritePin(IN2_1_GPIO_Port, IN2_1_Pin, GPIO_PIN_RESET);
    	  HAL_GPIO_WritePin(IN3_1_GPIO_Port, IN3_1_Pin, GPIO_PIN_RESET);
    	  HAL_GPIO_WritePin(IN4_1_GPIO_Port, IN4_1_Pin, GPIO_PIN_RESET);
    	  HAL_GPIO_WritePin(IN1_2_GPIO_Port, IN1_2_Pin, GPIO_PIN_RESET);
    	  HAL_GPIO_WritePin(IN2_2_GPIO_Port, IN2_2_Pin, GPIO_PIN_SET);
    	  HAL_GPIO_WritePin(IN3_2_GPIO_Port, IN3_2_Pin, GPIO_PIN_RESET);
    	  HAL_GPIO_WritePin(IN4_2_GPIO_Port, IN4_2_Pin, GPIO_PIN_SET);
    	  HAL_GPIO_WritePin(GPIOB, GPIO_PIN_13, GPIO_PIN_SET);
    	  __HAL_TIM_SET_COMPARE(&htim1, TIM_CHANNEL_3, 40);
    	  __HAL_TIM_SET_COMPARE(&htim1, TIM_CHANNEL_4, 40);
	  	    	}
	  else if (rx_byte == 0x12){
    	  HAL_GPIO_WritePin(IN1_1_GPIO_Port, IN1_1_Pin, GPIO_PIN_RESET);
    	  HAL_GPIO_WritePin(IN2_1_GPIO_Port, IN2_1_Pin, GPIO_PIN_RESET);
    	  HAL_GPIO_WritePin(IN3_1_GPIO_Port, IN3_1_Pin, GPIO_PIN_RESET);
    	  HAL_GPIO_WritePin(IN4_1_GPIO_Port, IN4_1_Pin, GPIO_PIN_RESET);
    	  HAL_GPIO_WritePin(IN1_2_GPIO_Port, IN1_2_Pin, GPIO_PIN_RESET);
    	  HAL_GPIO_WritePin(IN2_2_GPIO_Port, IN2_2_Pin, GPIO_PIN_SET);
    	  HAL_GPIO_WritePin(IN3_2_GPIO_Port, IN3_2_Pin, GPIO_PIN_RESET);
    	  HAL_GPIO_WritePin(IN4_2_GPIO_Port, IN4_2_Pin, GPIO_PIN_SET);
    	  HAL_GPIO_WritePin(GPIOB, GPIO_PIN_13, GPIO_PIN_SET);
    	  __HAL_TIM_SET_COMPARE(&htim1, TIM_CHANNEL_3, 60);
    	  __HAL_TIM_SET_COMPARE(&htim1, TIM_CHANNEL_4, 60);
	  	    	}
	  else if (rx_byte == 0x13){
    	  HAL_GPIO_WritePin(IN1_1_GPIO_Port, IN1_1_Pin, GPIO_PIN_RESET);
    	  HAL_GPIO_WritePin(IN2_1_GPIO_Port, IN2_1_Pin, GPIO_PIN_RESET);
    	  HAL_GPIO_WritePin(IN3_1_GPIO_Port, IN3_1_Pin, GPIO_PIN_RESET);
    	  HAL_GPIO_WritePin(IN4_1_GPIO_Port, IN4_1_Pin, GPIO_PIN_RESET);
    	  HAL_GPIO_WritePin(IN1_2_GPIO_Port, IN1_2_Pin, GPIO_PIN_RESET);
    	  HAL_GPIO_WritePin(IN2_2_GPIO_Port, IN2_2_Pin, GPIO_PIN_SET);
    	  HAL_GPIO_WritePin(IN3_2_GPIO_Port, IN3_2_Pin, GPIO_PIN_RESET);
    	  HAL_GPIO_WritePin(IN4_2_GPIO_Port, IN4_2_Pin, GPIO_PIN_SET);
    	  HAL_GPIO_WritePin(GPIOB, GPIO_PIN_13, GPIO_PIN_SET);
    	  __HAL_TIM_SET_COMPARE(&htim1, TIM_CHANNEL_3, 80);
    	  __HAL_TIM_SET_COMPARE(&htim1, TIM_CHANNEL_4, 80);
	  	    	}
	  else if (rx_byte == 0x14){
    	  HAL_GPIO_WritePin(IN1_1_GPIO_Port, IN1_1_Pin, GPIO_PIN_RESET);
    	  HAL_GPIO_WritePin(IN2_1_GPIO_Port, IN2_1_Pin, GPIO_PIN_RESET);
    	  HAL_GPIO_WritePin(IN3_1_GPIO_Port, IN3_1_Pin, GPIO_PIN_RESET);
    	  HAL_GPIO_WritePin(IN4_1_GPIO_Port, IN4_1_Pin, GPIO_PIN_RESET);
    	  HAL_GPIO_WritePin(IN1_2_GPIO_Port, IN1_2_Pin, GPIO_PIN_RESET);
    	  HAL_GPIO_WritePin(IN2_2_GPIO_Port, IN2_2_Pin, GPIO_PIN_SET);
    	  HAL_GPIO_WritePin(IN3_2_GPIO_Port, IN3_2_Pin, GPIO_PIN_RESET);
    	  HAL_GPIO_WritePin(IN4_2_GPIO_Port, IN4_2_Pin, GPIO_PIN_SET);
    	  HAL_GPIO_WritePin(GPIOB, GPIO_PIN_13, GPIO_PIN_SET);
    	  __HAL_TIM_SET_COMPARE(&htim1, TIM_CHANNEL_3, 100);
    	  __HAL_TIM_SET_COMPARE(&htim1, TIM_CHANNEL_4, 100);
	  	    	}
	  else if (rx_byte == 0x15){
    	  HAL_GPIO_WritePin(IN1_1_GPIO_Port, IN1_1_Pin, GPIO_PIN_SET);
    	  HAL_GPIO_WritePin(IN2_1_GPIO_Port, IN2_1_Pin, GPIO_PIN_RESET);
    	  HAL_GPIO_WritePin(IN3_1_GPIO_Port, IN3_1_Pin, GPIO_PIN_RESET);
    	  HAL_GPIO_WritePin(IN4_1_GPIO_Port, IN4_1_Pin, GPIO_PIN_RESET);
    	  HAL_GPIO_WritePin(IN1_2_GPIO_Port, IN1_2_Pin, GPIO_PIN_RESET);
    	  HAL_GPIO_WritePin(IN2_2_GPIO_Port, IN2_2_Pin, GPIO_PIN_RESET);
    	  HAL_GPIO_WritePin(IN3_2_GPIO_Port, IN3_2_Pin, GPIO_PIN_SET);
    	  HAL_GPIO_WritePin(IN4_2_GPIO_Port, IN4_2_Pin, GPIO_PIN_RESET);
    	  HAL_GPIO_WritePin(GPIOB, GPIO_PIN_13, GPIO_PIN_SET);
    	  __HAL_TIM_SET_COMPARE(&htim1, TIM_CHANNEL_1, 20);
    	  __HAL_TIM_SET_COMPARE(&htim1, TIM_CHANNEL_4, 20);
	  	    	}
	  else if (rx_byte == 0x16){
    	  HAL_GPIO_WritePin(IN1_1_GPIO_Port, IN1_1_Pin, GPIO_PIN_SET);
    	  HAL_GPIO_WritePin(IN2_1_GPIO_Port, IN2_1_Pin, GPIO_PIN_RESET);
    	  HAL_GPIO_WritePin(IN3_1_GPIO_Port, IN3_1_Pin, GPIO_PIN_RESET);
    	  HAL_GPIO_WritePin(IN4_1_GPIO_Port, IN4_1_Pin, GPIO_PIN_RESET);
    	  HAL_GPIO_WritePin(IN1_2_GPIO_Port, IN1_2_Pin, GPIO_PIN_RESET);
    	  HAL_GPIO_WritePin(IN2_2_GPIO_Port, IN2_2_Pin, GPIO_PIN_RESET);
    	  HAL_GPIO_WritePin(IN3_2_GPIO_Port, IN3_2_Pin, GPIO_PIN_SET);
    	  HAL_GPIO_WritePin(IN4_2_GPIO_Port, IN4_2_Pin, GPIO_PIN_RESET);
    	  HAL_GPIO_WritePin(GPIOB, GPIO_PIN_13, GPIO_PIN_SET);
    	  __HAL_TIM_SET_COMPARE(&htim1, TIM_CHANNEL_1, 40);
    	  __HAL_TIM_SET_COMPARE(&htim1, TIM_CHANNEL_4, 40);
	  	    	}
	  else if (rx_byte == 0x17){
    	  HAL_GPIO_WritePin(IN1_1_GPIO_Port, IN1_1_Pin, GPIO_PIN_SET);
    	  HAL_GPIO_WritePin(IN2_1_GPIO_Port, IN2_1_Pin, GPIO_PIN_RESET);
    	  HAL_GPIO_WritePin(IN3_1_GPIO_Port, IN3_1_Pin, GPIO_PIN_RESET);
    	  HAL_GPIO_WritePin(IN4_1_GPIO_Port, IN4_1_Pin, GPIO_PIN_RESET);
    	  HAL_GPIO_WritePin(IN1_2_GPIO_Port, IN1_2_Pin, GPIO_PIN_RESET);
    	  HAL_GPIO_WritePin(IN2_2_GPIO_Port, IN2_2_Pin, GPIO_PIN_RESET);
    	  HAL_GPIO_WritePin(IN3_2_GPIO_Port, IN3_2_Pin, GPIO_PIN_SET);
    	  HAL_GPIO_WritePin(IN4_2_GPIO_Port, IN4_2_Pin, GPIO_PIN_RESET);
    	  HAL_GPIO_WritePin(GPIOB, GPIO_PIN_13, GPIO_PIN_SET);
    	  __HAL_TIM_SET_COMPARE(&htim1, TIM_CHANNEL_1, 60);
    	  __HAL_TIM_SET_COMPARE(&htim1, TIM_CHANNEL_4, 60);
	  	    	}
	  else if (rx_byte == 0x18){
    	  HAL_GPIO_WritePin(IN1_1_GPIO_Port, IN1_1_Pin, GPIO_PIN_SET);
    	  HAL_GPIO_WritePin(IN2_1_GPIO_Port, IN2_1_Pin, GPIO_PIN_RESET);
    	  HAL_GPIO_WritePin(IN3_1_GPIO_Port, IN3_1_Pin, GPIO_PIN_RESET);
    	  HAL_GPIO_WritePin(IN4_1_GPIO_Port, IN4_1_Pin, GPIO_PIN_RESET);
    	  HAL_GPIO_WritePin(IN1_2_GPIO_Port, IN1_2_Pin, GPIO_PIN_RESET);
    	  HAL_GPIO_WritePin(IN2_2_GPIO_Port, IN2_2_Pin, GPIO_PIN_RESET);
    	  HAL_GPIO_WritePin(IN3_2_GPIO_Port, IN3_2_Pin, GPIO_PIN_SET);
    	  HAL_GPIO_WritePin(IN4_2_GPIO_Port, IN4_2_Pin, GPIO_PIN_RESET);
    	  HAL_GPIO_WritePin(GPIOB, GPIO_PIN_13, GPIO_PIN_SET);
    	  __HAL_TIM_SET_COMPARE(&htim1, TIM_CHANNEL_1, 80);
    	  __HAL_TIM_SET_COMPARE(&htim1, TIM_CHANNEL_4, 80);
	  	    	}
	  else if (rx_byte == 0x19){
    	  HAL_GPIO_WritePin(IN1_1_GPIO_Port, IN1_1_Pin, GPIO_PIN_SET);
    	  HAL_GPIO_WritePin(IN2_1_GPIO_Port, IN2_1_Pin, GPIO_PIN_RESET);
    	  HAL_GPIO_WritePin(IN3_1_GPIO_Port, IN3_1_Pin, GPIO_PIN_RESET);
    	  HAL_GPIO_WritePin(IN4_1_GPIO_Port, IN4_1_Pin, GPIO_PIN_RESET);
    	  HAL_GPIO_WritePin(IN1_2_GPIO_Port, IN1_2_Pin, GPIO_PIN_RESET);
    	  HAL_GPIO_WritePin(IN2_2_GPIO_Port, IN2_2_Pin, GPIO_PIN_RESET);
    	  HAL_GPIO_WritePin(IN3_2_GPIO_Port, IN3_2_Pin, GPIO_PIN_SET);
    	  HAL_GPIO_WritePin(IN4_2_GPIO_Port, IN4_2_Pin, GPIO_PIN_RESET);
    	  HAL_GPIO_WritePin(GPIOB, GPIO_PIN_13, GPIO_PIN_SET);
    	  __HAL_TIM_SET_COMPARE(&htim1, TIM_CHANNEL_1, 100);
    	  __HAL_TIM_SET_COMPARE(&htim1, TIM_CHANNEL_4, 100);
	  	    	}
	  else if (rx_byte == 0x1A){
    	  HAL_GPIO_WritePin(IN1_1_GPIO_Port, IN1_1_Pin, GPIO_PIN_RESET);
    	  HAL_GPIO_WritePin(IN2_1_GPIO_Port, IN2_1_Pin, GPIO_PIN_SET);
    	  HAL_GPIO_WritePin(IN3_1_GPIO_Port, IN3_1_Pin, GPIO_PIN_RESET);
    	  HAL_GPIO_WritePin(IN4_1_GPIO_Port, IN4_1_Pin, GPIO_PIN_RESET);
    	  HAL_GPIO_WritePin(IN1_2_GPIO_Port, IN1_2_Pin, GPIO_PIN_RESET);
    	  HAL_GPIO_WritePin(IN2_2_GPIO_Port, IN2_2_Pin, GPIO_PIN_RESET);
    	  HAL_GPIO_WritePin(IN3_2_GPIO_Port, IN3_2_Pin, GPIO_PIN_RESET);
    	  HAL_GPIO_WritePin(IN4_2_GPIO_Port, IN4_2_Pin, GPIO_PIN_SET);
    	  HAL_GPIO_WritePin(GPIOB, GPIO_PIN_13, GPIO_PIN_SET);
    	  __HAL_TIM_SET_COMPARE(&htim1, TIM_CHANNEL_1, 20);
    	  __HAL_TIM_SET_COMPARE(&htim1, TIM_CHANNEL_4, 20);
	  	    	}
	  else if (rx_byte == 0x1B){
    	  HAL_GPIO_WritePin(IN1_1_GPIO_Port, IN1_1_Pin, GPIO_PIN_RESET);
    	  HAL_GPIO_WritePin(IN2_1_GPIO_Port, IN2_1_Pin, GPIO_PIN_SET);
    	  HAL_GPIO_WritePin(IN3_1_GPIO_Port, IN3_1_Pin, GPIO_PIN_RESET);
    	  HAL_GPIO_WritePin(IN4_1_GPIO_Port, IN4_1_Pin, GPIO_PIN_RESET);
    	  HAL_GPIO_WritePin(IN1_2_GPIO_Port, IN1_2_Pin, GPIO_PIN_RESET);
    	  HAL_GPIO_WritePin(IN2_2_GPIO_Port, IN2_2_Pin, GPIO_PIN_RESET);
    	  HAL_GPIO_WritePin(IN3_2_GPIO_Port, IN3_2_Pin, GPIO_PIN_RESET);
    	  HAL_GPIO_WritePin(IN4_2_GPIO_Port, IN4_2_Pin, GPIO_PIN_SET);
    	  HAL_GPIO_WritePin(GPIOB, GPIO_PIN_13, GPIO_PIN_SET);
    	  __HAL_TIM_SET_COMPARE(&htim1, TIM_CHANNEL_1, 40);
    	  __HAL_TIM_SET_COMPARE(&htim1, TIM_CHANNEL_4, 40);
	  	    	}
	  else if (rx_byte == 0x1C){
    	  HAL_GPIO_WritePin(IN1_1_GPIO_Port, IN1_1_Pin, GPIO_PIN_RESET);
    	  HAL_GPIO_WritePin(IN2_1_GPIO_Port, IN2_1_Pin, GPIO_PIN_SET);
    	  HAL_GPIO_WritePin(IN3_1_GPIO_Port, IN3_1_Pin, GPIO_PIN_RESET);
    	  HAL_GPIO_WritePin(IN4_1_GPIO_Port, IN4_1_Pin, GPIO_PIN_RESET);
    	  HAL_GPIO_WritePin(IN1_2_GPIO_Port, IN1_2_Pin, GPIO_PIN_RESET);
    	  HAL_GPIO_WritePin(IN2_2_GPIO_Port, IN2_2_Pin, GPIO_PIN_RESET);
    	  HAL_GPIO_WritePin(IN3_2_GPIO_Port, IN3_2_Pin, GPIO_PIN_RESET);
    	  HAL_GPIO_WritePin(IN4_2_GPIO_Port, IN4_2_Pin, GPIO_PIN_SET);
    	  HAL_GPIO_WritePin(GPIOB, GPIO_PIN_13, GPIO_PIN_SET);
    	  __HAL_TIM_SET_COMPARE(&htim1, TIM_CHANNEL_1, 60);
    	  __HAL_TIM_SET_COMPARE(&htim1, TIM_CHANNEL_4, 60);
	  	    	}
	  else if (rx_byte == 0x1D){
    	  HAL_GPIO_WritePin(IN1_1_GPIO_Port, IN1_1_Pin, GPIO_PIN_RESET);
    	  HAL_GPIO_WritePin(IN2_1_GPIO_Port, IN2_1_Pin, GPIO_PIN_SET);
    	  HAL_GPIO_WritePin(IN3_1_GPIO_Port, IN3_1_Pin, GPIO_PIN_RESET);
    	  HAL_GPIO_WritePin(IN4_1_GPIO_Port, IN4_1_Pin, GPIO_PIN_RESET);
    	  HAL_GPIO_WritePin(IN1_2_GPIO_Port, IN1_2_Pin, GPIO_PIN_RESET);
    	  HAL_GPIO_WritePin(IN2_2_GPIO_Port, IN2_2_Pin, GPIO_PIN_RESET);
    	  HAL_GPIO_WritePin(IN3_2_GPIO_Port, IN3_2_Pin, GPIO_PIN_RESET);
    	  HAL_GPIO_WritePin(IN4_2_GPIO_Port, IN4_2_Pin, GPIO_PIN_SET);
    	  HAL_GPIO_WritePin(GPIOB, GPIO_PIN_13, GPIO_PIN_SET);
    	  __HAL_TIM_SET_COMPARE(&htim1, TIM_CHANNEL_1, 80);
    	  __HAL_TIM_SET_COMPARE(&htim1, TIM_CHANNEL_4, 80);
	  	    	}
	  else if (rx_byte == 0x1E){
    	  HAL_GPIO_WritePin(IN1_1_GPIO_Port, IN1_1_Pin, GPIO_PIN_RESET);
    	  HAL_GPIO_WritePin(IN2_1_GPIO_Port, IN2_1_Pin, GPIO_PIN_SET);
    	  HAL_GPIO_WritePin(IN3_1_GPIO_Port, IN3_1_Pin, GPIO_PIN_RESET);
    	  HAL_GPIO_WritePin(IN4_1_GPIO_Port, IN4_1_Pin, GPIO_PIN_RESET);
    	  HAL_GPIO_WritePin(IN1_2_GPIO_Port, IN1_2_Pin, GPIO_PIN_RESET);
    	  HAL_GPIO_WritePin(IN2_2_GPIO_Port, IN2_2_Pin, GPIO_PIN_RESET);
    	  HAL_GPIO_WritePin(IN3_2_GPIO_Port, IN3_2_Pin, GPIO_PIN_RESET);
    	  HAL_GPIO_WritePin(IN4_2_GPIO_Port, IN4_2_Pin, GPIO_PIN_SET);
    	  HAL_GPIO_WritePin(GPIOB, GPIO_PIN_13, GPIO_PIN_SET);
    	  __HAL_TIM_SET_COMPARE(&htim1, TIM_CHANNEL_1, 100);
    	  __HAL_TIM_SET_COMPARE(&htim1, TIM_CHANNEL_4, 100);
	  	    	}
	  else if (rx_byte == 0x1F){
    	  HAL_GPIO_WritePin(IN1_1_GPIO_Port, IN1_1_Pin, GPIO_PIN_RESET);
    	  HAL_GPIO_WritePin(IN2_1_GPIO_Port, IN2_1_Pin, GPIO_PIN_RESET);
    	  HAL_GPIO_WritePin(IN3_1_GPIO_Port, IN3_1_Pin, GPIO_PIN_SET);
    	  HAL_GPIO_WritePin(IN4_1_GPIO_Port, IN4_1_Pin, GPIO_PIN_RESET);
    	  HAL_GPIO_WritePin(IN1_2_GPIO_Port, IN1_2_Pin, GPIO_PIN_SET);
    	  HAL_GPIO_WritePin(IN2_2_GPIO_Port, IN2_2_Pin, GPIO_PIN_RESET);
    	  HAL_GPIO_WritePin(IN3_2_GPIO_Port, IN3_2_Pin, GPIO_PIN_RESET);
    	  HAL_GPIO_WritePin(IN4_2_GPIO_Port, IN4_2_Pin, GPIO_PIN_RESET);
    	  HAL_GPIO_WritePin(GPIOB, GPIO_PIN_13, GPIO_PIN_SET);
    	  __HAL_TIM_SET_COMPARE(&htim1, TIM_CHANNEL_2, 20);
    	  __HAL_TIM_SET_COMPARE(&htim1, TIM_CHANNEL_3, 20);
	  	    	}
	  else if (rx_byte == 0x20){
    	  HAL_GPIO_WritePin(IN1_1_GPIO_Port, IN1_1_Pin, GPIO_PIN_RESET);
    	  HAL_GPIO_WritePin(IN2_1_GPIO_Port, IN2_1_Pin, GPIO_PIN_RESET);
    	  HAL_GPIO_WritePin(IN3_1_GPIO_Port, IN3_1_Pin, GPIO_PIN_SET);
    	  HAL_GPIO_WritePin(IN4_1_GPIO_Port, IN4_1_Pin, GPIO_PIN_RESET);
    	  HAL_GPIO_WritePin(IN1_2_GPIO_Port, IN1_2_Pin, GPIO_PIN_SET);
    	  HAL_GPIO_WritePin(IN2_2_GPIO_Port, IN2_2_Pin, GPIO_PIN_RESET);
    	  HAL_GPIO_WritePin(IN3_2_GPIO_Port, IN3_2_Pin, GPIO_PIN_RESET);
    	  HAL_GPIO_WritePin(IN4_2_GPIO_Port, IN4_2_Pin, GPIO_PIN_RESET);
    	  HAL_GPIO_WritePin(GPIOB, GPIO_PIN_13, GPIO_PIN_SET);
    	  __HAL_TIM_SET_COMPARE(&htim1, TIM_CHANNEL_2, 40);
    	  __HAL_TIM_SET_COMPARE(&htim1, TIM_CHANNEL_3, 40);
	  	    	}
	  else if (rx_byte == 0x21){
    	  HAL_GPIO_WritePin(IN1_1_GPIO_Port, IN1_1_Pin, GPIO_PIN_RESET);
    	  HAL_GPIO_WritePin(IN2_1_GPIO_Port, IN2_1_Pin, GPIO_PIN_RESET);
    	  HAL_GPIO_WritePin(IN3_1_GPIO_Port, IN3_1_Pin, GPIO_PIN_SET);
    	  HAL_GPIO_WritePin(IN4_1_GPIO_Port, IN4_1_Pin, GPIO_PIN_RESET);
    	  HAL_GPIO_WritePin(IN1_2_GPIO_Port, IN1_2_Pin, GPIO_PIN_SET);
    	  HAL_GPIO_WritePin(IN2_2_GPIO_Port, IN2_2_Pin, GPIO_PIN_RESET);
    	  HAL_GPIO_WritePin(IN3_2_GPIO_Port, IN3_2_Pin, GPIO_PIN_RESET);
    	  HAL_GPIO_WritePin(IN4_2_GPIO_Port, IN4_2_Pin, GPIO_PIN_RESET);
    	  HAL_GPIO_WritePin(GPIOB, GPIO_PIN_13, GPIO_PIN_SET);
    	  __HAL_TIM_SET_COMPARE(&htim1, TIM_CHANNEL_2, 60);
    	  __HAL_TIM_SET_COMPARE(&htim1, TIM_CHANNEL_3, 60);
	  	    	}
	  else if (rx_byte == 0x22){
    	  HAL_GPIO_WritePin(IN1_1_GPIO_Port, IN1_1_Pin, GPIO_PIN_RESET);
    	  HAL_GPIO_WritePin(IN2_1_GPIO_Port, IN2_1_Pin, GPIO_PIN_RESET);
    	  HAL_GPIO_WritePin(IN3_1_GPIO_Port, IN3_1_Pin, GPIO_PIN_SET);
    	  HAL_GPIO_WritePin(IN4_1_GPIO_Port, IN4_1_Pin, GPIO_PIN_RESET);
    	  HAL_GPIO_WritePin(IN1_2_GPIO_Port, IN1_2_Pin, GPIO_PIN_SET);
    	  HAL_GPIO_WritePin(IN2_2_GPIO_Port, IN2_2_Pin, GPIO_PIN_RESET);
    	  HAL_GPIO_WritePin(IN3_2_GPIO_Port, IN3_2_Pin, GPIO_PIN_RESET);
    	  HAL_GPIO_WritePin(IN4_2_GPIO_Port, IN4_2_Pin, GPIO_PIN_RESET);
    	  HAL_GPIO_WritePin(GPIOB, GPIO_PIN_13, GPIO_PIN_SET);
    	  __HAL_TIM_SET_COMPARE(&htim1, TIM_CHANNEL_2, 80);
    	  __HAL_TIM_SET_COMPARE(&htim1, TIM_CHANNEL_3, 80);
	  	    	}
	  else if (rx_byte == 0x23){
    	  HAL_GPIO_WritePin(IN1_1_GPIO_Port, IN1_1_Pin, GPIO_PIN_RESET);
    	  HAL_GPIO_WritePin(IN2_1_GPIO_Port, IN2_1_Pin, GPIO_PIN_RESET);
    	  HAL_GPIO_WritePin(IN3_1_GPIO_Port, IN3_1_Pin, GPIO_PIN_SET);
    	  HAL_GPIO_WritePin(IN4_1_GPIO_Port, IN4_1_Pin, GPIO_PIN_RESET);
    	  HAL_GPIO_WritePin(IN1_2_GPIO_Port, IN1_2_Pin, GPIO_PIN_SET);
    	  HAL_GPIO_WritePin(IN2_2_GPIO_Port, IN2_2_Pin, GPIO_PIN_RESET);
    	  HAL_GPIO_WritePin(IN3_2_GPIO_Port, IN3_2_Pin, GPIO_PIN_RESET);
    	  HAL_GPIO_WritePin(IN4_2_GPIO_Port, IN4_2_Pin, GPIO_PIN_RESET);
    	  HAL_GPIO_WritePin(GPIOB, GPIO_PIN_13, GPIO_PIN_SET);
    	  __HAL_TIM_SET_COMPARE(&htim1, TIM_CHANNEL_2, 100);
    	  __HAL_TIM_SET_COMPARE(&htim1, TIM_CHANNEL_3, 100);
	  	    	}
	  else if (rx_byte == 0x24){
    	  HAL_GPIO_WritePin(IN1_1_GPIO_Port, IN1_1_Pin, GPIO_PIN_RESET);
    	  HAL_GPIO_WritePin(IN2_1_GPIO_Port, IN2_1_Pin, GPIO_PIN_RESET);
    	  HAL_GPIO_WritePin(IN3_1_GPIO_Port, IN3_1_Pin, GPIO_PIN_RESET);
    	  HAL_GPIO_WritePin(IN4_1_GPIO_Port, IN4_1_Pin, GPIO_PIN_SET);
    	  HAL_GPIO_WritePin(IN1_2_GPIO_Port, IN1_2_Pin, GPIO_PIN_RESET);
    	  HAL_GPIO_WritePin(IN2_2_GPIO_Port, IN2_2_Pin, GPIO_PIN_SET);
    	  HAL_GPIO_WritePin(IN3_2_GPIO_Port, IN3_2_Pin, GPIO_PIN_RESET);
    	  HAL_GPIO_WritePin(IN4_2_GPIO_Port, IN4_2_Pin, GPIO_PIN_RESET);
    	  HAL_GPIO_WritePin(GPIOB, GPIO_PIN_13, GPIO_PIN_SET);
    	  __HAL_TIM_SET_COMPARE(&htim1, TIM_CHANNEL_2, 20);
    	  __HAL_TIM_SET_COMPARE(&htim1, TIM_CHANNEL_3, 20);
	  	    	}
	  else if (rx_byte == 0x25){
    	  HAL_GPIO_WritePin(IN1_1_GPIO_Port, IN1_1_Pin, GPIO_PIN_RESET);
    	  HAL_GPIO_WritePin(IN2_1_GPIO_Port, IN2_1_Pin, GPIO_PIN_RESET);
    	  HAL_GPIO_WritePin(IN3_1_GPIO_Port, IN3_1_Pin, GPIO_PIN_RESET);
    	  HAL_GPIO_WritePin(IN4_1_GPIO_Port, IN4_1_Pin, GPIO_PIN_SET);
    	  HAL_GPIO_WritePin(IN1_2_GPIO_Port, IN1_2_Pin, GPIO_PIN_RESET);
    	  HAL_GPIO_WritePin(IN2_2_GPIO_Port, IN2_2_Pin, GPIO_PIN_SET);
    	  HAL_GPIO_WritePin(IN3_2_GPIO_Port, IN3_2_Pin, GPIO_PIN_RESET);
    	  HAL_GPIO_WritePin(IN4_2_GPIO_Port, IN4_2_Pin, GPIO_PIN_RESET);
    	  HAL_GPIO_WritePin(GPIOB, GPIO_PIN_13, GPIO_PIN_SET);
    	  __HAL_TIM_SET_COMPARE(&htim1, TIM_CHANNEL_2, 40);
    	  __HAL_TIM_SET_COMPARE(&htim1, TIM_CHANNEL_3, 40);
	  	    	}
	  else if (rx_byte == 0x26){
    	  HAL_GPIO_WritePin(IN1_1_GPIO_Port, IN1_1_Pin, GPIO_PIN_RESET);
    	  HAL_GPIO_WritePin(IN2_1_GPIO_Port, IN2_1_Pin, GPIO_PIN_RESET);
    	  HAL_GPIO_WritePin(IN3_1_GPIO_Port, IN3_1_Pin, GPIO_PIN_RESET);
    	  HAL_GPIO_WritePin(IN4_1_GPIO_Port, IN4_1_Pin, GPIO_PIN_SET);
    	  HAL_GPIO_WritePin(IN1_2_GPIO_Port, IN1_2_Pin, GPIO_PIN_RESET);
    	  HAL_GPIO_WritePin(IN2_2_GPIO_Port, IN2_2_Pin, GPIO_PIN_SET);
    	  HAL_GPIO_WritePin(IN3_2_GPIO_Port, IN3_2_Pin, GPIO_PIN_RESET);
    	  HAL_GPIO_WritePin(IN4_2_GPIO_Port, IN4_2_Pin, GPIO_PIN_RESET);
    	  HAL_GPIO_WritePin(GPIOB, GPIO_PIN_13, GPIO_PIN_SET);
    	  __HAL_TIM_SET_COMPARE(&htim1, TIM_CHANNEL_2, 60);
    	  __HAL_TIM_SET_COMPARE(&htim1, TIM_CHANNEL_3, 60);
	  	    	}
	  else if (rx_byte == 0x27){
    	  HAL_GPIO_WritePin(IN1_1_GPIO_Port, IN1_1_Pin, GPIO_PIN_RESET);
    	  HAL_GPIO_WritePin(IN2_1_GPIO_Port, IN2_1_Pin, GPIO_PIN_RESET);
    	  HAL_GPIO_WritePin(IN3_1_GPIO_Port, IN3_1_Pin, GPIO_PIN_RESET);
    	  HAL_GPIO_WritePin(IN4_1_GPIO_Port, IN4_1_Pin, GPIO_PIN_SET);
    	  HAL_GPIO_WritePin(IN1_2_GPIO_Port, IN1_2_Pin, GPIO_PIN_RESET);
    	  HAL_GPIO_WritePin(IN2_2_GPIO_Port, IN2_2_Pin, GPIO_PIN_SET);
    	  HAL_GPIO_WritePin(IN3_2_GPIO_Port, IN3_2_Pin, GPIO_PIN_RESET);
    	  HAL_GPIO_WritePin(IN4_2_GPIO_Port, IN4_2_Pin, GPIO_PIN_RESET);
    	  HAL_GPIO_WritePin(GPIOB, GPIO_PIN_13, GPIO_PIN_SET);
    	  __HAL_TIM_SET_COMPARE(&htim1, TIM_CHANNEL_2, 80);
    	  __HAL_TIM_SET_COMPARE(&htim1, TIM_CHANNEL_3, 80);
	  	    	}
	  else if (rx_byte == 0x28){
    	  HAL_GPIO_WritePin(IN1_1_GPIO_Port, IN1_1_Pin, GPIO_PIN_RESET);
    	  HAL_GPIO_WritePin(IN2_1_GPIO_Port, IN2_1_Pin, GPIO_PIN_RESET);
    	  HAL_GPIO_WritePin(IN3_1_GPIO_Port, IN3_1_Pin, GPIO_PIN_RESET);
    	  HAL_GPIO_WritePin(IN4_1_GPIO_Port, IN4_1_Pin, GPIO_PIN_SET);
    	  HAL_GPIO_WritePin(IN1_2_GPIO_Port, IN1_2_Pin, GPIO_PIN_RESET);
    	  HAL_GPIO_WritePin(IN2_2_GPIO_Port, IN2_2_Pin, GPIO_PIN_SET);
    	  HAL_GPIO_WritePin(IN3_2_GPIO_Port, IN3_2_Pin, GPIO_PIN_RESET);
    	  HAL_GPIO_WritePin(IN4_2_GPIO_Port, IN4_2_Pin, GPIO_PIN_RESET);
    	  HAL_GPIO_WritePin(GPIOB, GPIO_PIN_13, GPIO_PIN_SET);
    	  __HAL_TIM_SET_COMPARE(&htim1, TIM_CHANNEL_2, 100);
    	  __HAL_TIM_SET_COMPARE(&htim1, TIM_CHANNEL_3, 100);
	  	    	}
	  else if (rx_byte == 0x29){
    	  HAL_GPIO_WritePin(IN1_1_GPIO_Port, IN1_1_Pin, GPIO_PIN_SET);
    	  HAL_GPIO_WritePin(IN2_1_GPIO_Port, IN2_1_Pin, GPIO_PIN_RESET);
    	  HAL_GPIO_WritePin(IN3_1_GPIO_Port, IN3_1_Pin, GPIO_PIN_SET);
    	  HAL_GPIO_WritePin(IN4_1_GPIO_Port, IN4_1_Pin, GPIO_PIN_RESET);
    	  HAL_GPIO_WritePin(IN1_2_GPIO_Port, IN1_2_Pin, GPIO_PIN_SET);
    	  HAL_GPIO_WritePin(IN2_2_GPIO_Port, IN2_2_Pin, GPIO_PIN_RESET);
    	  HAL_GPIO_WritePin(IN3_2_GPIO_Port, IN3_2_Pin, GPIO_PIN_SET);
    	  HAL_GPIO_WritePin(IN4_2_GPIO_Port, IN4_2_Pin, GPIO_PIN_RESET);
    	  HAL_GPIO_WritePin(GPIOB, GPIO_PIN_13, GPIO_PIN_SET);
    	  __HAL_TIM_SET_COMPARE(&htim1, TIM_CHANNEL_1, 20);
    	  __HAL_TIM_SET_COMPARE(&htim1, TIM_CHANNEL_2, 20);
    	  __HAL_TIM_SET_COMPARE(&htim1, TIM_CHANNEL_3, 20);
    	  __HAL_TIM_SET_COMPARE(&htim1, TIM_CHANNEL_4, 20);
	  	    	}
	  else if (rx_byte == 0x2A){
    	  HAL_GPIO_WritePin(IN1_1_GPIO_Port, IN1_1_Pin, GPIO_PIN_SET);
    	  HAL_GPIO_WritePin(IN2_1_GPIO_Port, IN2_1_Pin, GPIO_PIN_RESET);
    	  HAL_GPIO_WritePin(IN3_1_GPIO_Port, IN3_1_Pin, GPIO_PIN_SET);
    	  HAL_GPIO_WritePin(IN4_1_GPIO_Port, IN4_1_Pin, GPIO_PIN_RESET);
    	  HAL_GPIO_WritePin(IN1_2_GPIO_Port, IN1_2_Pin, GPIO_PIN_SET);
    	  HAL_GPIO_WritePin(IN2_2_GPIO_Port, IN2_2_Pin, GPIO_PIN_RESET);
    	  HAL_GPIO_WritePin(IN3_2_GPIO_Port, IN3_2_Pin, GPIO_PIN_SET);
    	  HAL_GPIO_WritePin(IN4_2_GPIO_Port, IN4_2_Pin, GPIO_PIN_RESET);
    	  HAL_GPIO_WritePin(GPIOB, GPIO_PIN_13, GPIO_PIN_SET);
    	  __HAL_TIM_SET_COMPARE(&htim1, TIM_CHANNEL_1, 40);
    	  __HAL_TIM_SET_COMPARE(&htim1, TIM_CHANNEL_2, 40);
    	  __HAL_TIM_SET_COMPARE(&htim1, TIM_CHANNEL_3, 40);
    	  __HAL_TIM_SET_COMPARE(&htim1, TIM_CHANNEL_4, 40);
	  	    	}
	  else if (rx_byte == 0x2B){
    	  HAL_GPIO_WritePin(IN1_1_GPIO_Port, IN1_1_Pin, GPIO_PIN_SET);
    	  HAL_GPIO_WritePin(IN2_1_GPIO_Port, IN2_1_Pin, GPIO_PIN_RESET);
    	  HAL_GPIO_WritePin(IN3_1_GPIO_Port, IN3_1_Pin, GPIO_PIN_SET);
    	  HAL_GPIO_WritePin(IN4_1_GPIO_Port, IN4_1_Pin, GPIO_PIN_RESET);
    	  HAL_GPIO_WritePin(IN1_2_GPIO_Port, IN1_2_Pin, GPIO_PIN_SET);
    	  HAL_GPIO_WritePin(IN2_2_GPIO_Port, IN2_2_Pin, GPIO_PIN_RESET);
    	  HAL_GPIO_WritePin(IN3_2_GPIO_Port, IN3_2_Pin, GPIO_PIN_SET);
    	  HAL_GPIO_WritePin(IN4_2_GPIO_Port, IN4_2_Pin, GPIO_PIN_RESET);
    	  HAL_GPIO_WritePin(GPIOB, GPIO_PIN_13, GPIO_PIN_SET);
    	  __HAL_TIM_SET_COMPARE(&htim1, TIM_CHANNEL_1, 60);
    	  __HAL_TIM_SET_COMPARE(&htim1, TIM_CHANNEL_2, 60);
    	  __HAL_TIM_SET_COMPARE(&htim1, TIM_CHANNEL_3, 60);
    	  __HAL_TIM_SET_COMPARE(&htim1, TIM_CHANNEL_4, 60);
	  	    	}
	  else if (rx_byte == 0x2C){
    	  HAL_GPIO_WritePin(IN1_1_GPIO_Port, IN1_1_Pin, GPIO_PIN_SET);
    	  HAL_GPIO_WritePin(IN2_1_GPIO_Port, IN2_1_Pin, GPIO_PIN_RESET);
    	  HAL_GPIO_WritePin(IN3_1_GPIO_Port, IN3_1_Pin, GPIO_PIN_SET);
    	  HAL_GPIO_WritePin(IN4_1_GPIO_Port, IN4_1_Pin, GPIO_PIN_RESET);
    	  HAL_GPIO_WritePin(IN1_2_GPIO_Port, IN1_2_Pin, GPIO_PIN_SET);
    	  HAL_GPIO_WritePin(IN2_2_GPIO_Port, IN2_2_Pin, GPIO_PIN_RESET);
    	  HAL_GPIO_WritePin(IN3_2_GPIO_Port, IN3_2_Pin, GPIO_PIN_SET);
    	  HAL_GPIO_WritePin(IN4_2_GPIO_Port, IN4_2_Pin, GPIO_PIN_RESET);
    	  HAL_GPIO_WritePin(GPIOB, GPIO_PIN_13, GPIO_PIN_SET);
    	  __HAL_TIM_SET_COMPARE(&htim1, TIM_CHANNEL_1, 80);
    	  __HAL_TIM_SET_COMPARE(&htim1, TIM_CHANNEL_2, 80);
    	  __HAL_TIM_SET_COMPARE(&htim1, TIM_CHANNEL_3, 80);
    	  __HAL_TIM_SET_COMPARE(&htim1, TIM_CHANNEL_4, 80);
	  	    	}
	  else if (rx_byte == 0x2D){
    	  HAL_GPIO_WritePin(IN1_1_GPIO_Port, IN1_1_Pin, GPIO_PIN_SET);
    	  HAL_GPIO_WritePin(IN2_1_GPIO_Port, IN2_1_Pin, GPIO_PIN_RESET);
    	  HAL_GPIO_WritePin(IN3_1_GPIO_Port, IN3_1_Pin, GPIO_PIN_SET);
    	  HAL_GPIO_WritePin(IN4_1_GPIO_Port, IN4_1_Pin, GPIO_PIN_RESET);
    	  HAL_GPIO_WritePin(IN1_2_GPIO_Port, IN1_2_Pin, GPIO_PIN_SET);
    	  HAL_GPIO_WritePin(IN2_2_GPIO_Port, IN2_2_Pin, GPIO_PIN_RESET);
    	  HAL_GPIO_WritePin(IN3_2_GPIO_Port, IN3_2_Pin, GPIO_PIN_SET);
    	  HAL_GPIO_WritePin(IN4_2_GPIO_Port, IN4_2_Pin, GPIO_PIN_RESET);
    	  HAL_GPIO_WritePin(GPIOB, GPIO_PIN_13, GPIO_PIN_SET);
    	  __HAL_TIM_SET_COMPARE(&htim1, TIM_CHANNEL_1, 100);
    	  __HAL_TIM_SET_COMPARE(&htim1, TIM_CHANNEL_2, 100);
    	  __HAL_TIM_SET_COMPARE(&htim1, TIM_CHANNEL_3, 100);
    	  __HAL_TIM_SET_COMPARE(&htim1, TIM_CHANNEL_4, 100);
	  	    	}
	  else if (rx_byte == 0x2E){
    	  HAL_GPIO_WritePin(IN1_1_GPIO_Port, IN1_1_Pin, GPIO_PIN_RESET);
    	  HAL_GPIO_WritePin(IN2_1_GPIO_Port, IN2_1_Pin, GPIO_PIN_SET);
    	  HAL_GPIO_WritePin(IN3_1_GPIO_Port, IN3_1_Pin, GPIO_PIN_RESET);
    	  HAL_GPIO_WritePin(IN4_1_GPIO_Port, IN4_1_Pin, GPIO_PIN_SET);
    	  HAL_GPIO_WritePin(IN1_2_GPIO_Port, IN1_2_Pin, GPIO_PIN_RESET);
    	  HAL_GPIO_WritePin(IN2_2_GPIO_Port, IN2_2_Pin, GPIO_PIN_SET);
    	  HAL_GPIO_WritePin(IN3_2_GPIO_Port, IN3_2_Pin, GPIO_PIN_RESET);
    	  HAL_GPIO_WritePin(IN4_2_GPIO_Port, IN4_2_Pin, GPIO_PIN_SET);
    	  HAL_GPIO_WritePin(GPIOB, GPIO_PIN_13, GPIO_PIN_SET);
    	  __HAL_TIM_SET_COMPARE(&htim1, TIM_CHANNEL_1, 20);
    	  __HAL_TIM_SET_COMPARE(&htim1, TIM_CHANNEL_2, 20);
    	  __HAL_TIM_SET_COMPARE(&htim1, TIM_CHANNEL_3, 20);
    	  __HAL_TIM_SET_COMPARE(&htim1, TIM_CHANNEL_4, 20);
	  	    	}
	  else if (rx_byte == 0x2F){
    	  HAL_GPIO_WritePin(IN1_1_GPIO_Port, IN1_1_Pin, GPIO_PIN_RESET);
    	  HAL_GPIO_WritePin(IN2_1_GPIO_Port, IN2_1_Pin, GPIO_PIN_SET);
    	  HAL_GPIO_WritePin(IN3_1_GPIO_Port, IN3_1_Pin, GPIO_PIN_RESET);
    	  HAL_GPIO_WritePin(IN4_1_GPIO_Port, IN4_1_Pin, GPIO_PIN_SET);
    	  HAL_GPIO_WritePin(IN1_2_GPIO_Port, IN1_2_Pin, GPIO_PIN_RESET);
    	  HAL_GPIO_WritePin(IN2_2_GPIO_Port, IN2_2_Pin, GPIO_PIN_SET);
    	  HAL_GPIO_WritePin(IN3_2_GPIO_Port, IN3_2_Pin, GPIO_PIN_RESET);
    	  HAL_GPIO_WritePin(IN4_2_GPIO_Port, IN4_2_Pin, GPIO_PIN_SET);
    	  HAL_GPIO_WritePin(GPIOB, GPIO_PIN_13, GPIO_PIN_SET);
    	  __HAL_TIM_SET_COMPARE(&htim1, TIM_CHANNEL_1, 40);
    	  __HAL_TIM_SET_COMPARE(&htim1, TIM_CHANNEL_2, 40);
    	  __HAL_TIM_SET_COMPARE(&htim1, TIM_CHANNEL_3, 40);
    	  __HAL_TIM_SET_COMPARE(&htim1, TIM_CHANNEL_4, 40);
	  	    	}
	  else if (rx_byte == 0x30){
    	  HAL_GPIO_WritePin(IN1_1_GPIO_Port, IN1_1_Pin, GPIO_PIN_RESET);
    	  HAL_GPIO_WritePin(IN2_1_GPIO_Port, IN2_1_Pin, GPIO_PIN_SET);
    	  HAL_GPIO_WritePin(IN3_1_GPIO_Port, IN3_1_Pin, GPIO_PIN_RESET);
    	  HAL_GPIO_WritePin(IN4_1_GPIO_Port, IN4_1_Pin, GPIO_PIN_SET);
    	  HAL_GPIO_WritePin(IN1_2_GPIO_Port, IN1_2_Pin, GPIO_PIN_RESET);
    	  HAL_GPIO_WritePin(IN2_2_GPIO_Port, IN2_2_Pin, GPIO_PIN_SET);
    	  HAL_GPIO_WritePin(IN3_2_GPIO_Port, IN3_2_Pin, GPIO_PIN_RESET);
    	  HAL_GPIO_WritePin(IN4_2_GPIO_Port, IN4_2_Pin, GPIO_PIN_SET);
    	  HAL_GPIO_WritePin(GPIOB, GPIO_PIN_13, GPIO_PIN_SET);
    	  __HAL_TIM_SET_COMPARE(&htim1, TIM_CHANNEL_1, 60);
    	  __HAL_TIM_SET_COMPARE(&htim1, TIM_CHANNEL_2, 60);
    	  __HAL_TIM_SET_COMPARE(&htim1, TIM_CHANNEL_3, 60);
    	  __HAL_TIM_SET_COMPARE(&htim1, TIM_CHANNEL_4, 60);
	  	    	}
	  else if (rx_byte == 0x31){
    	  HAL_GPIO_WritePin(IN1_1_GPIO_Port, IN1_1_Pin, GPIO_PIN_RESET);
    	  HAL_GPIO_WritePin(IN2_1_GPIO_Port, IN2_1_Pin, GPIO_PIN_SET);
    	  HAL_GPIO_WritePin(IN3_1_GPIO_Port, IN3_1_Pin, GPIO_PIN_RESET);
    	  HAL_GPIO_WritePin(IN4_1_GPIO_Port, IN4_1_Pin, GPIO_PIN_SET);
    	  HAL_GPIO_WritePin(IN1_2_GPIO_Port, IN1_2_Pin, GPIO_PIN_RESET);
    	  HAL_GPIO_WritePin(IN2_2_GPIO_Port, IN2_2_Pin, GPIO_PIN_SET);
    	  HAL_GPIO_WritePin(IN3_2_GPIO_Port, IN3_2_Pin, GPIO_PIN_RESET);
    	  HAL_GPIO_WritePin(IN4_2_GPIO_Port, IN4_2_Pin, GPIO_PIN_SET);
    	  HAL_GPIO_WritePin(GPIOB, GPIO_PIN_13, GPIO_PIN_SET);
    	  __HAL_TIM_SET_COMPARE(&htim1, TIM_CHANNEL_1, 80);
    	  __HAL_TIM_SET_COMPARE(&htim1, TIM_CHANNEL_2, 80);
    	  __HAL_TIM_SET_COMPARE(&htim1, TIM_CHANNEL_3, 80);
    	  __HAL_TIM_SET_COMPARE(&htim1, TIM_CHANNEL_4, 80);
	  	    	}
	  else if (rx_byte == 0x32){
    	  HAL_GPIO_WritePin(IN1_1_GPIO_Port, IN1_1_Pin, GPIO_PIN_RESET);
    	  HAL_GPIO_WritePin(IN2_1_GPIO_Port, IN2_1_Pin, GPIO_PIN_SET);
    	  HAL_GPIO_WritePin(IN3_1_GPIO_Port, IN3_1_Pin, GPIO_PIN_RESET);
    	  HAL_GPIO_WritePin(IN4_1_GPIO_Port, IN4_1_Pin, GPIO_PIN_SET);
    	  HAL_GPIO_WritePin(IN1_2_GPIO_Port, IN1_2_Pin, GPIO_PIN_RESET);
    	  HAL_GPIO_WritePin(IN2_2_GPIO_Port, IN2_2_Pin, GPIO_PIN_SET);
    	  HAL_GPIO_WritePin(IN3_2_GPIO_Port, IN3_2_Pin, GPIO_PIN_RESET);
    	  HAL_GPIO_WritePin(IN4_2_GPIO_Port, IN4_2_Pin, GPIO_PIN_SET);
    	  HAL_GPIO_WritePin(GPIOB, GPIO_PIN_13, GPIO_PIN_SET);
    	  __HAL_TIM_SET_COMPARE(&htim1, TIM_CHANNEL_1, 100);
    	  __HAL_TIM_SET_COMPARE(&htim1, TIM_CHANNEL_2, 100);
    	  __HAL_TIM_SET_COMPARE(&htim1, TIM_CHANNEL_3, 100);
    	  __HAL_TIM_SET_COMPARE(&htim1, TIM_CHANNEL_4, 100);
	  }
      else {
    	  HAL_GPIO_WritePin(IN1_1_GPIO_Port, IN1_1_Pin, GPIO_PIN_RESET);
    	  HAL_GPIO_WritePin(IN2_1_GPIO_Port, IN2_1_Pin, GPIO_PIN_RESET);
	      HAL_GPIO_WritePin(IN3_1_GPIO_Port, IN3_1_Pin, GPIO_PIN_RESET);
	      HAL_GPIO_WritePin(IN4_1_GPIO_Port, IN4_1_Pin, GPIO_PIN_RESET);
	      HAL_GPIO_WritePin(IN1_2_GPIO_Port, IN1_2_Pin, GPIO_PIN_RESET);
	      HAL_GPIO_WritePin(IN2_2_GPIO_Port, IN2_2_Pin, GPIO_PIN_RESET);
	      HAL_GPIO_WritePin(IN3_2_GPIO_Port, IN3_2_Pin, GPIO_PIN_RESET);
	      HAL_GPIO_WritePin(IN4_2_GPIO_Port, IN4_2_Pin, GPIO_PIN_RESET);
    	  HAL_GPIO_WritePin(GPIOB, GPIO_PIN_13, GPIO_PIN_RESET);
    	  __HAL_TIM_SET_COMPARE(&htim1, TIM_CHANNEL_1, 0);
    	  __HAL_TIM_SET_COMPARE(&htim1, TIM_CHANNEL_2, 0);
    	  __HAL_TIM_SET_COMPARE(&htim1, TIM_CHANNEL_3, 0);
    	  __HAL_TIM_SET_COMPARE(&htim1, TIM_CHANNEL_4, 0);
      }
    }
}

/* USER CODE END 4 */

void Error_Handler(void)
{
  __disable_irq();
  while (1)
  {
  }
}
